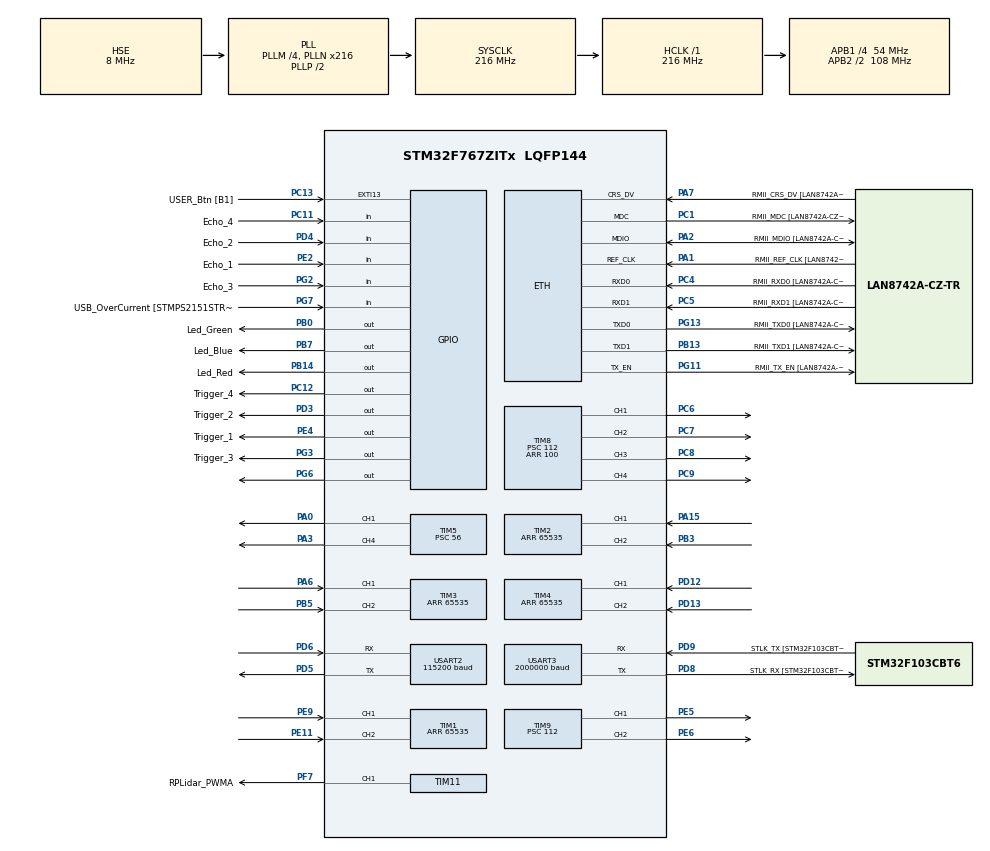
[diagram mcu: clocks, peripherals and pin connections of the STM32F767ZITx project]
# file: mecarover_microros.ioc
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CORTEX_M7.AccessPermission-Cortex_Memory_Protection_Unit_Region1_Settings=MPU_REGION_FULL_ACCESS
CORTEX_M7.AccessPermission-Cortex_Memory_Protection_Unit_Region2_Settings=MPU_REGION_FULL_ACCESS
CORTEX_M7.BaseAddress-Cortex_Memory_Protection_Unit_Region1_Settings=0x30004000
CORTEX_M7.BaseAddress-Cortex_Memory_Protection_Unit_Region2_Settings=0x2007c000
CORTEX_M7.CPU_DCache=Enabled
CORTEX_M7.CPU_ICache=Enabled
CORTEX_M7.DisableExec-Cortex_Memory_Protection_Unit_Region1_Settings=MPU_INSTRUCTION_ACCESS_DISABLE
CORTEX_M7.DisableExec-Cortex_Memory_Protection_Unit_Region2_Settings=MPU_INSTRUCTION_ACCESS_DISABLE
CORTEX_M7.Enable-Cortex_Memory_Protection_Unit_Region1_Settings=MPU_REGION_ENABLE
CORTEX_M7.Enable-Cortex_Memory_Protection_Unit_Region2_Settings=MPU_REGION_ENABLE
CORTEX_M7.IsBufferable-Cortex_Memory_Protection_Unit_Region2_Settings=MPU_ACCESS_BUFFERABLE
CORTEX_M7.IsShareable-Cortex_Memory_Protection_Unit_Region2_Settings=MPU_ACCESS_SHAREABLE
CORTEX_M7.MPU_Control=MPU_PRIVILEGED_DEFAULT
CORTEX_M7.Size-Cortex_Memory_Protection_Unit_Region1_Settings=MPU_REGION_SIZE_16KB
CORTEX_M7.Size-Cortex_Memory_Protection_Unit_Region2_Settings=MPU_REGION_SIZE_512B
Dma.Request0=USART2_RX
Dma.Request1=USART2_TX
Dma.Request2=USART3_TX
Dma.USART2_RX.0.Direction=DMA_PERIPH_TO_MEMORY
Dma.USART2_RX.0.FIFOMode=DMA_FIFOMODE_DISABLE
Dma.USART2_RX.0.Instance=DMA1_Stream5
Dma.USART2_RX.0.MemDataAlignment=DMA_MDATAALIGN_BYTE
Dma.USART2_RX.0.MemInc=DMA_MINC_ENABLE
Dma.USART2_RX.0.Mode=DMA_CIRCULAR
Dma.USART2_RX.0.PeriphDataAlignment=DMA_PDATAALIGN_BYTE
Dma.USART2_RX.0.PeriphInc=DMA_PINC_DISABLE
Dma.USART2_RX.0.Priority=DMA_PRIORITY_VERY_HIGH
Dma.USART2_TX.1.Direction=DMA_MEMORY_TO_PERIPH
Dma.USART2_TX.1.FIFOMode=DMA_FIFOMODE_DISABLE
Dma.USART2_TX.1.Instance=DMA1_Stream6
Dma.USART2_TX.1.MemDataAlignment=DMA_MDATAALIGN_BYTE
Dma.USART2_TX.1.MemInc=DMA_MINC_ENABLE
Dma.USART2_TX.1.Mode=DMA_NORMAL
Dma.USART2_TX.1.PeriphDataAlignment=DMA_PDATAALIGN_BYTE
Dma.USART2_TX.1.PeriphInc=DMA_PINC_DISABLE
Dma.USART2_TX.1.Priority=DMA_PRIORITY_VERY_HIGH
Dma.USART3_TX.2.Direction=DMA_MEMORY_TO_PERIPH
Dma.USART3_TX.2.FIFOMode=DMA_FIFOMODE_DISABLE
Dma.USART3_TX.2.Instance=DMA1_Stream3
Dma.USART3_TX.2.MemDataAlignment=DMA_MDATAALIGN_BYTE
Dma.USART3_TX.2.MemInc=DMA_MINC_ENABLE
Dma.USART3_TX.2.Mode=DMA_NORMAL
Dma.USART3_TX.2.PeriphDataAlignment=DMA_PDATAALIGN_BYTE
Dma.USART3_TX.2.PeriphInc=DMA_PINC_DISABLE
Dma.USART3_TX.2.Priority=DMA_PRIORITY_LOW
ETH.MediaInterface=HAL_ETH_RMII_MODE
FREERTOS.Tasks01=defaultTask,8,128,none,Default,NULL,Dynamic,NULL,NULL
FREERTOS.configGENERATE_RUN_TIME_STATS=1
FREERTOS.configTOTAL_HEAP_SIZE=25000
FREERTOS.configUSE_NEWLIB_REENTRANT=1
FREERTOS.configUSE_STATS_FORMATTING_FUNCTIONS=1
LWIP.BSP.number=1
LWIP.GATEWAY_ADDRESS=192.168.001.255
LWIP.IP_ADDRESS=192.168.001.249
LWIP.LWIP_DHCP=0
LWIP.LWIP_DNS=1
LWIP.LWIP_SO_RCVTIMEO=1
LWIP.MEMP_NUM_TCP_SEG=17
LWIP.MEMP_NUM_UDP_PCB=15
LWIP.MEM_SIZE=16360
LWIP.NETMASK_ADDRESS=255.255.255.000
LWIP.TCP_MSS=1460
LWIP.TCP_SND_BUF=5840
LWIP.TCP_SND_QUEUELEN=16
LWIP.TCP_WND_UPDATE_THRESHOLD=5840
LWIP.Version=v2.1.2_Cube
LWIP0.BSP.STBoard=false
LWIP0.BSP.api=BSP_COMPONENT_DRIVER
LWIP0.BSP.component=LAN8742
LWIP0.BSP.instance=LAN8742
LWIP0.BSP.name=Driver_PHY
LWIP0.BSP.semaphore=S_LAN8742
LWIP0.BSP.solution=LAN8742
Mcu.Family=STM32F7
Mcu.Name=STM32F767ZITx
Mcu.Package=LQFP144
NVIC.DMA1_Stream3_IRQn=true\:5\:0\:false\:false\:true\:true\:true\:true\:true
NVIC.DMA1_Stream5_IRQn=true\:1\:0\:true\:false\:true\:false\:true\:true\:true
NVIC.DMA1_Stream6_IRQn=true\:5\:0\:false\:false\:true\:false\:true\:true\:true
NVIC.ETH_IRQn=true\:5\:0\:false\:false\:true\:true\:false\:true\:true
NVIC.EXTI15_10_IRQn=true\:5\:0\:false\:false\:true\:true\:true\:true\:true
NVIC.PriorityGroup=NVIC_PRIORITYGROUP_4
NVIC.TIM1_UP_TIM10_IRQn=true\:0\:0\:true\:false\:true\:false\:true\:true\:true
NVIC.TIM2_IRQn=true\:0\:0\:true\:false\:true\:false\:true\:true\:true
NVIC.TIM3_IRQn=true\:0\:0\:true\:false\:true\:false\:true\:true\:true
NVIC.TIM4_IRQn=true\:0\:0\:true\:false\:true\:false\:true\:true\:true
NVIC.TIM8_BRK_TIM12_IRQn=true\:15\:0\:false\:false\:true\:false\:false\:true\:true
NVIC.TIM8_UP_TIM13_IRQn=true\:5\:0\:false\:false\:true\:false\:true\:true\:true
NVIC.TimeBase=TIM8_BRK_TIM12_IRQn
NVIC.TimeBaseIP=TIM12
NVIC.USART2_IRQn=true\:1\:0\:true\:false\:true\:false\:true\:true\:true
NVIC.USART3_IRQn=true\:5\:0\:true\:false\:true\:true\:true\:true\:true
PA0/WKUP.Signal=S_TIM5_CH1
PA1.GPIO_Label=RMII_REF_CLK [LAN8742A-CZ-TR_REFCLK0]
PA1.Mode=RMII
PA1.Signal=ETH_REF_CLK
PA10.GPIO_Label=USB_ID
PA10.Signal=USB_OTG_FS_ID
PA11.GPIO_Label=USB_DM
PA11.Signal=USB_OTG_FS_DM
PA12.GPIO_Label=USB_DP
PA12.Signal=USB_OTG_FS_DP
PA13.GPIO_Label=TMS
PA13.Mode=Serial_Wire
PA13.Signal=SYS_JTMS-SWDIO
PA14.GPIO_Label=TCK
PA14.Mode=Serial_Wire
PA14.Signal=SYS_JTCK-SWCLK
PA15.Signal=S_TIM2_CH1_ETR
PA2.GPIO_Label=RMII_MDIO [LAN8742A-CZ-TR_MDIO]
PA2.Mode=RMII
PA2.Signal=ETH_MDIO
PA3.Signal=S_TIM5_CH4
PA6.Signal=S_TIM3_CH1
PA7.GPIO_Label=RMII_CRS_DV [LAN8742A-CZ-TR_CRS_DV]
PA7.Mode=RMII
PA7.Signal=ETH_CRS_DV
PA8.GPIO_Label=USB_SOF [TP1]
PA8.Signal=USB_OTG_FS_SOF
PA9.GPIO_Label=USB_VBUS
PA9.Signal=USB_OTG_FS_VBUS
PB0.GPIO_Label=Led_Green
PB0.Signal=GPIO_Output
PB13.GPIO_Label=RMII_TXD1 [LAN8742A-CZ-TR_TXD1]
PB13.Mode=RMII
PB13.Signal=ETH_TXD1
PB14.GPIO_Label=Led_Red
PB14.Signal=GPIO_Output
PB3.Signal=S_TIM2_CH2
PB5.Signal=S_TIM3_CH2
PB7.GPIO_Label=Led_Blue
PB7.Signal=GPIO_Output
PC1.GPIO_Label=RMII_MDC [LAN8742A-CZ-TR_MDC]
PC1.Mode=RMII
PC1.Signal=ETH_MDC
PC11.GPIO_Label=Echo_4
PC11.Signal=GPIO_Input
PC12.GPIO_Label=Trigger_4
PC12.Signal=GPIO_Output
PC13.GPIO_Label=USER_Btn [B1]
PC13.Signal=GPXTI13
PC14/OSC32_IN.Mode=LSE-External-Oscillator
PC14/OSC32_IN.Signal=RCC_OSC32_IN
PC15/OSC32_OUT.Mode=LSE-External-Oscillator
PC15/OSC32_OUT.Signal=RCC_OSC32_OUT
PC4.GPIO_Label=RMII_RXD0 [LAN8742A-CZ-TR_RXD0]
PC4.Mode=RMII
PC4.Signal=ETH_RXD0
PC5.GPIO_Label=RMII_RXD1 [LAN8742A-CZ-TR_RXD1]
PC5.Mode=RMII
PC5.Signal=ETH_RXD1
PC6.Signal=S_TIM8_CH1
PC7.Signal=S_TIM8_CH2
PC8.Signal=S_TIM8_CH3
PC9.Signal=S_TIM8_CH4
PD12.Signal=S_TIM4_CH1
PD13.Signal=S_TIM4_CH2
PD3.GPIO_Label=Trigger_2
PD3.Signal=GPIO_Output
PD4.GPIO_Label=Echo_2
PD4.Signal=GPIO_Input
PD5.Mode=Asynchronous
PD5.Signal=USART2_TX
PD6.Mode=Asynchronous
PD6.Signal=USART2_RX
PD8.GPIO_Label=STLK_RX [STM32F103CBT6_PA3]
PD8.Mode=Asynchronous
PD8.Signal=USART3_TX
PD9.GPIO_Label=STLK_TX [STM32F103CBT6_PA2]
PD9.Mode=Asynchronous
PD9.Signal=USART3_RX
PE11.Signal=S_TIM1_CH2
PE2.GPIO_Label=Echo_1
PE2.Signal=GPIO_Input
PE4.GPIO_Label=Trigger_1
PE4.Signal=GPIO_Output
PE5.Signal=S_TIM9_CH1
PE6.Signal=S_TIM9_CH2
PE9.Signal=S_TIM1_CH1
PF7.GPIO_Label=RPLidar_PWMA
PF7.Signal=S_TIM11_CH1
PG11.GPIO_Label=RMII_TX_EN [LAN8742A-CZ-TR_TXEN]
PG11.Mode=RMII
PG11.Signal=ETH_TX_EN
PG13.GPIO_Label=RMII_TXD0 [LAN8742A-CZ-TR_TXD0]
PG13.Mode=RMII
PG13.Signal=ETH_TXD0
PG2.GPIO_Label=Echo_3
PG2.Signal=GPIO_Input
PG3.GPIO_Label=Trigger_3
PG3.Signal=GPIO_Output
PG6.Signal=GPIO_Output
PG7.GPIO_Label=USB_OverCurrent [STMPS2151STR_FAULT]
PG7.Signal=GPIO_Input
PH0/OSC_IN.GPIO_Label=MCO [STM32F103CBT6_PA8]
PH0/OSC_IN.Mode=HSE-External-Oscillator
PH0/OSC_IN.Signal=RCC_OSC_IN
PH1/OSC_OUT.Mode=HSE-External-Oscillator
PH1/OSC_OUT.Signal=RCC_OSC_OUT
ProjectManager.HeapSize=0x200
ProjectManager.StackSize=0x400
ProjectManager.TargetToolchain=Makefile
RCC.48MHZClocksFreq_Value=24000000
RCC.AHBFreq_Value=216000000
RCC.APB1CLKDivider=RCC_HCLK_DIV4
RCC.APB1Freq_Value=54000000
RCC.APB1TimFreq_Value=108000000
RCC.APB2CLKDivider=RCC_HCLK_DIV2
RCC.APB2Freq_Value=108000000
RCC.APB2TimFreq_Value=216000000
RCC.CortexFreq_Value=216000000
RCC.HCLKFreq_Value=216000000
RCC.HSE_VALUE=8000000
RCC.HSI_VALUE=16000000
RCC.PLLM=4
RCC.PLLMUL=RCC_PLL_MUL9
RCC.PLLN=216
RCC.PLLQ=9
RCC.PLLSourceVirtual=RCC_PLLSOURCE_HSE
RCC.PRESCALERUSB=RCC_USBCLKSOURCE_PLL_DIV1_5
RCC.SYSCLKFreq_VALUE=216000000
RCC.SYSCLKSource=RCC_SYSCLKSOURCE_PLLCLK
RCC.SYSCLKSourceVirtual=RCC_SYSCLKSOURCE_PLLCLK
RCC.USBFreq_Value=48000000
RCC.VCOOutputFreq_Value=432000000
SH.S_TIM11_CH1.0=TIM11_CH1,PWM Generation1 CH1
SH.S_TIM1_CH1.0=TIM1_CH1,Encoder_Interface
SH.S_TIM1_CH2.0=TIM1_CH2,Encoder_Interface
SH.S_TIM2_CH1_ETR.0=TIM2_CH1,Encoder_Interface
SH.S_TIM2_CH2.0=TIM2_CH2,Encoder_Interface
SH.S_TIM3_CH1.0=TIM3_CH1,Encoder_Interface
SH.S_TIM3_CH2.0=TIM3_CH2,Encoder_Interface
SH.S_TIM4_CH1.0=TIM4_CH1,Encoder_Interface
SH.S_TIM4_CH2.0=TIM4_CH2,Encoder_Interface
SH.S_TIM5_CH1.0=TIM5_CH1,PWM Generation1 CH1
SH.S_TIM5_CH4.0=TIM5_CH4,PWM Generation4 CH4
SH.S_TIM8_CH1.0=TIM8_CH1,PWM Generation1 CH1
SH.S_TIM8_CH2.0=TIM8_CH2,PWM Generation2 CH2
SH.S_TIM8_CH3.0=TIM8_CH3,PWM Generation3 CH3
SH.S_TIM8_CH4.0=TIM8_CH4,PWM Generation4 CH4
SH.S_TIM9_CH1.0=TIM9_CH1,PWM Generation1 CH1
SH.S_TIM9_CH2.0=TIM9_CH2,PWM Generation2 CH2
TIM1.AutoReloadPreload=TIM_AUTORELOAD_PRELOAD_DISABLE
TIM1.EncoderMode=TIM_ENCODERMODE_TI12
TIM1.IC1Polarity=TIM_ICPOLARITY_RISING
TIM1.IC2Polarity=TIM_ICPOLARITY_RISING
TIM1.Period=65535
TIM11.Channel=TIM_CHANNEL_1
TIM11.Period=6000
TIM11.Prescaler=6535
TIM13.Period=10000
TIM2.AutoReloadPreload=TIM_AUTORELOAD_PRELOAD_DISABLE
TIM2.EncoderMode=TIM_ENCODERMODE_TI12
TIM2.IC1Polarity=TIM_ICPOLARITY_RISING
TIM2.IC2Polarity=TIM_ICPOLARITY_RISING
TIM2.Period=65535
TIM3.AutoReloadPreload=TIM_AUTORELOAD_PRELOAD_DISABLE
TIM3.EncoderMode=TIM_ENCODERMODE_TI12
TIM3.IC1Polarity=TIM_ICPOLARITY_RISING
TIM3.IC2Polarity=TIM_ICPOLARITY_RISING
TIM3.Period=65535
TIM4.AutoReloadPreload=TIM_AUTORELOAD_PRELOAD_DISABLE
TIM4.EncoderMode=TIM_ENCODERMODE_TI12
TIM4.IC1Polarity=TIM_ICPOLARITY_RISING
TIM4.IC2Polarity=TIM_ICPOLARITY_RISING
TIM4.Period=65535
TIM5.Channel-PWM\ Generation1\ CH1=TIM_CHANNEL_1
TIM5.Channel-PWM\ Generation4\ CH4=TIM_CHANNEL_4
TIM5.Period=100
TIM5.Prescaler=56
TIM8.Channel-PWM\ Generation1\ CH1=TIM_CHANNEL_1
TIM8.Channel-PWM\ Generation2\ CH2=TIM_CHANNEL_2
TIM8.Channel-PWM\ Generation3\ CH3=TIM_CHANNEL_3
TIM8.Channel-PWM\ Generation4\ CH4=TIM_CHANNEL_4
TIM8.Period=100
TIM8.Prescaler=112
TIM9.Channel-PWM\ Generation1\ CH1=TIM_CHANNEL_1
TIM9.Channel-PWM\ Generation2\ CH2=TIM_CHANNEL_2
TIM9.Period=100
TIM9.Prescaler=112
USART2.BaudRate=115200
USART2.SwapParam=ADVFEATURE_SWAP_DISABLE
USART2.VirtualMode-Asynchronous=VM_ASYNC
USART3.BaudRate=2000000
USART3.StopBits=STOPBITS_1
USART3.VirtualMode-Asynchronous=VM_ASYNC
VP_FREERTOS_VS_CMSIS_V2.Mode=CMSIS_V2
VP_LWIP_VS_Enabled.Mode=Enabled
VP_RTC_VS_RTC_Activate.Mode=RTC_Enabled
VP_SYS_VS_tim12.Mode=TIM12
VP_TIM11_VS_ClockSourceINT.Mode=Enable_Timer
VP_TIM13_VS_ClockSourceINT.Mode=Enable_Timer
board=NUCLEO-F767ZI

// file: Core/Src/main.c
/* USER CODE BEGIN Header */
/**
  ******************************************************************************
  * @file           : main.c
  * @brief          : Main program body
  ******************************************************************************
  * @attention
  *
  * Copyright (c) 2024 STMicroelectronics.
  * All rights reserved.
  *
  * This software is licensed under terms that can be found in the LICENSE file
  * in the root directory of this software component.
  * If no LICENSE file comes with this software, it is provided AS-IS.
  *
  ******************************************************************************
  */
/* USER CODE END Header */
#include "main.h"
#include "cmsis_os.h"
#include "dma.h"
#include "lwip.h"
#include "rtc.h"
#include "tim.h"
#include "usart.h"
#include "gpio.h"

/* USER CODE BEGIN Includes */
#include <application/hal/hal.hpp>
/* USER CODE END Includes */

void SystemClock_Config(void);
static void MPU_Config(void);
void MX_FREERTOS_Init(void);
/* USER CODE BEGIN PFP */
extern void MX_FREERTOS_Init(void);

/* USER CODE END PFP */

int main(void)
{

  /* MPU Configuration--------------------------------------------------------*/
  MPU_Config();

  /* Enable the CPU Cache */

  /* Enable I-Cache---------------------------------------------------------*/
  SCB_EnableICache();

  /* Enable D-Cache---------------------------------------------------------*/
  SCB_EnableDCache();

  /* MCU Configuration--------------------------------------------------------*/

  /* Reset of all peripherals, Initializes the Flash interface and the Systick. */
  HAL_Init();

  /* Configure the system clock */
  SystemClock_Config();

  /* Initialize all configured peripherals */
  MX_GPIO_Init();
  MX_DMA_Init();
  MX_TIM1_Init();
  MX_TIM3_Init();
  MX_TIM4_Init();
  MX_TIM5_Init();
  MX_TIM8_Init();
  MX_TIM9_Init();
  MX_USART3_UART_Init();
  MX_TIM2_Init();
  MX_USART2_UART_Init();
  MX_TIM11_Init();
  MX_TIM13_Init();
  MX_RTC_Init();

  /* Init scheduler */
  osKernelInitialize();

  /* Call init function for freertos objects (in cmsis_os2.c) */
  MX_FREERTOS_Init();

  /* Start scheduler */
  osKernelStart();

  /* We should never get here as control is now taken by the scheduler */

  /* Infinite loop */
  while (1)
  {

  }
}

void SystemClock_Config(void)
{
  RCC_OscInitTypeDef RCC_OscInitStruct = {0};
  RCC_ClkInitTypeDef RCC_ClkInitStruct = {0};

  /** Configure LSE Drive Capability
  */
  HAL_PWR_EnableBkUpAccess();

  /** Configure the main internal regulator output voltage
  */
  __HAL_RCC_PWR_CLK_ENABLE();
  __HAL_PWR_VOLTAGESCALING_CONFIG(PWR_REGULATOR_VOLTAGE_SCALE1);

  /** Initializes the RCC Oscillators according to the specified parameters
  * in the RCC_OscInitTypeDef structure.
  */
  RCC_OscInitStruct.OscillatorType = RCC_OSCILLATORTYPE_LSI|RCC_OSCILLATORTYPE_HSE;
  RCC_OscInitStruct.HSEState = RCC_HSE_ON;
  RCC_OscInitStruct.LSIState = RCC_LSI_ON;
  RCC_OscInitStruct.PLL.PLLState = RCC_PLL_ON;
  RCC_OscInitStruct.PLL.PLLSource = RCC_PLLSOURCE_HSE;
  RCC_OscInitStruct.PLL.PLLM = 4;
  RCC_OscInitStruct.PLL.PLLN = 216;
  RCC_OscInitStruct.PLL.PLLP = RCC_PLLP_DIV2;
  RCC_OscInitStruct.PLL.PLLQ = 9;
  RCC_OscInitStruct.PLL.PLLR = 2;
  if (HAL_RCC_OscConfig(&RCC_OscInitStruct) != HAL_OK)
  {
    Error_Handler();
  }

  /** Activate the Over-Drive mode
  */
  if (HAL_PWREx_EnableOverDrive() != HAL_OK)
  {
    Error_Handler();
  }

  /** Initializes the CPU, AHB and APB buses clocks
  */
  RCC_ClkInitStruct.ClockType = RCC_CLOCKTYPE_HCLK|RCC_CLOCKTYPE_SYSCLK
                              |RCC_CLOCKTYPE_PCLK1|RCC_CLOCKTYPE_PCLK2;
  RCC_ClkInitStruct.SYSCLKSource = RCC_SYSCLKSOURCE_PLLCLK;
  RCC_ClkInitStruct.AHBCLKDivider = RCC_SYSCLK_DIV1;
  RCC_ClkInitStruct.APB1CLKDivider = RCC_HCLK_DIV4;
  RCC_ClkInitStruct.APB2CLKDivider = RCC_HCLK_DIV2;

  if (HAL_RCC_ClockConfig(&RCC_ClkInitStruct, FLASH_LATENCY_7) != HAL_OK)
  {
    Error_Handler();
  }
}

 /* MPU Configuration */

void MPU_Config(void)
{
  MPU_Region_InitTypeDef MPU_InitStruct = {0};

  /* Disables the MPU */
  HAL_MPU_Disable();

  /** Initializes and configures the Region and the memory to be protected
  */
  MPU_InitStruct.Enable = MPU_REGION_ENABLE;
  MPU_InitStruct.Number = MPU_REGION_NUMBER1;
  MPU_InitStruct.BaseAddress = 0x30004000;
  MPU_InitStruct.Size = MPU_REGION_SIZE_16KB;
  MPU_InitStruct.SubRegionDisable = 0x0;
  MPU_InitStruct.TypeExtField = MPU_TEX_LEVEL0;
  MPU_InitStruct.AccessPermission = MPU_REGION_FULL_ACCESS;
  MPU_InitStruct.DisableExec = MPU_INSTRUCTION_ACCESS_DISABLE;
  MPU_InitStruct.IsShareable = MPU_ACCESS_NOT_SHAREABLE;
  MPU_InitStruct.IsCacheable = MPU_ACCESS_NOT_CACHEABLE;
  MPU_InitStruct.IsBufferable = MPU_ACCESS_NOT_BUFFERABLE;

  HAL_MPU_ConfigRegion(&MPU_InitStruct);

  /** Initializes and configures the Region and the memory to be protected
  */
  MPU_InitStruct.Number = MPU_REGION_NUMBER2;
  MPU_InitStruct.BaseAddress = 0x2007c000;
  MPU_InitStruct.Size = MPU_REGION_SIZE_512B;
  MPU_InitStruct.IsShareable = MPU_ACCESS_SHAREABLE;
  MPU_InitStruct.IsBufferable = MPU_ACCESS_BUFFERABLE;

  HAL_MPU_ConfigRegion(&MPU_InitStruct);
  /* Enables the MPU */
  HAL_MPU_Enable(MPU_PRIVILEGED_DEFAULT);

}

void HAL_TIM_PeriodElapsedCallback(TIM_HandleTypeDef *htim)
{
  if (htim->Instance == TIM12) {
    HAL_IncTick();
  }
  /* USER CODE BEGIN Callback 1 */
  encoder_tim_cb(htim);
  /* USER CODE END Callback 1 */
}

void Error_Handler(void)
{
  __disable_irq();
  while (1)
  {
  }
}

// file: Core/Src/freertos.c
/* USER CODE BEGIN Header */
/**
  ******************************************************************************
  * File Name          : freertos.c
  * Description        : Code for freertos applications
  ******************************************************************************
  * @attention
  *
  * Copyright (c) 2022 STMicroelectronics.
  * All rights reserved.
  *
  * This software is licensed under terms that can be found in the LICENSE file
  * in the root directory of this software component.
  * If no LICENSE file comes with this software, it is provided AS-IS.
  *
  ******************************************************************************
  */
/* USER CODE END Header */

#include "FreeRTOS.h"
#include "task.h"
#include "main.h"
#include "cmsis_os.h"

/* Definitions for defaultTask */
osThreadId_t defaultTaskHandle;
const osThreadAttr_t defaultTask_attributes = {
  .name = "defaultTask",
  .stack_size = 128 * 4,
  .priority = (osPriority_t) osPriorityLow,
};

/* USER CODE BEGIN FunctionPrototypes */
void application_start(void);
/* USER CODE END FunctionPrototypes */

void none(void *argument);

extern void MX_LWIP_Init(void);
void MX_FREERTOS_Init(void); /* (MISRA C 2004 rule 8.1) */

/* Hook prototypes */
void configureTimerForRunTimeStats(void);
unsigned long getRunTimeCounterValue(void);

/* USER CODE BEGIN 1 */
/* Functions needed when configGENERATE_RUN_TIME_STATS is on */
__weak void configureTimerForRunTimeStats(void)
{

}

__weak unsigned long getRunTimeCounterValue(void)
{
return 0;
}
/* USER CODE END 1 */

void MX_FREERTOS_Init(void) {
  /* USER CODE BEGIN Init */
  application_start(); // intercept and should never return
  /* USER CODE END Init */

  /* Create the thread(s) */
  /* creation of defaultTask */
  defaultTaskHandle = osThreadNew(none, NULL, &defaultTask_attributes);

}

void none(void *argument)
{
  /* init code for LWIP */
  MX_LWIP_Init();
  /* USER CODE BEGIN none */
  vTaskDelete(NULL);
  /* USER CODE END none */
}
